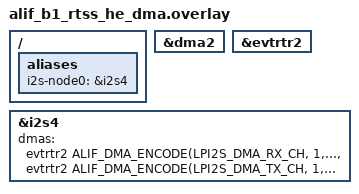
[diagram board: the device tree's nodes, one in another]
#include <zephyr/dt-bindings/dma/alif_dma_event_router.h>

#define LPI2S_DMA_RX_CH  4
#define LPI2S_DMA_RX_REQ 14
#define LPI2S_DMA_TX_CH  5
#define LPI2S_DMA_TX_REQ 15

/ {
	aliases {
		i2s-node0 = &i2s4;
	};
};

&dma2 {
	status = "okay";
};

&evtrtr2 {
	status = "okay";
};

i2s_rxtx: &i2s4 {
	status = "okay";
	dmas = <&evtrtr2 ALIF_DMA_ENCODE(LPI2S_DMA_RX_CH, 1, 1) LPI2S_DMA_RX_REQ>,
	       <&evtrtr2 ALIF_DMA_ENCODE(LPI2S_DMA_TX_CH, 1, 1) LPI2S_DMA_TX_REQ>;
	dma-names = "rxdma", "txdma";
};
